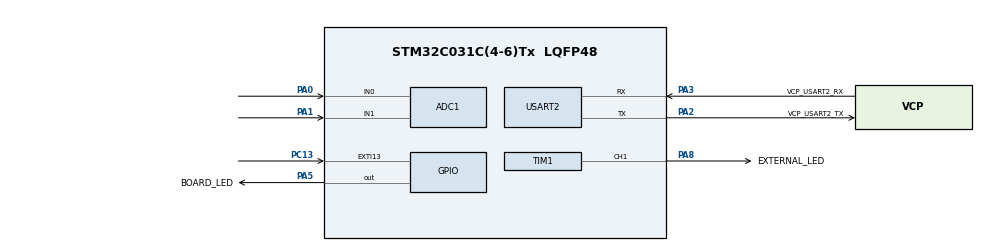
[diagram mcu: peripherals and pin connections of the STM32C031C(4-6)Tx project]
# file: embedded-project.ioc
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ADC1.ContinuousConvMode=ENABLE
ADC1.DMAContinuousRequests=ENABLE
ADC1.NbrOfConversionFlag=0
ADC1.Overrun=ADC_OVR_DATA_OVERWRITTEN
ADC1.SamplingTimeCommon1=ADC_SAMPLETIME_160CYCLES_5
ADC1.SelectedChannel=ADC_CHANNEL_0|ADC_CHANNEL_1
ADC1.master=1
Dma.ADC1.0.Direction=DMA_PERIPH_TO_MEMORY
Dma.ADC1.0.EventEnable=DISABLE
Dma.ADC1.0.Instance=DMA1_Channel1
Dma.ADC1.0.MemDataAlignment=DMA_MDATAALIGN_HALFWORD
Dma.ADC1.0.MemInc=DMA_MINC_ENABLE
Dma.ADC1.0.Mode=DMA_CIRCULAR
Dma.ADC1.0.PeriphDataAlignment=DMA_PDATAALIGN_HALFWORD
Dma.ADC1.0.PeriphInc=DMA_PINC_DISABLE
Dma.ADC1.0.Polarity=HAL_DMAMUX_REQ_GEN_RISING
Dma.ADC1.0.Priority=DMA_PRIORITY_LOW
Dma.ADC1.0.RequestNumber=1
Dma.ADC1.0.SignalID=NONE
Dma.ADC1.0.SyncEnable=DISABLE
Dma.ADC1.0.SyncPolarity=HAL_DMAMUX_SYNC_NO_EVENT
Dma.ADC1.0.SyncRequestNumber=1
Dma.ADC1.0.SyncSignalID=NONE
Dma.Request0=ADC1
Mcu.Family=STM32C0
Mcu.Name=STM32C031C(4-6)Tx
Mcu.Package=LQFP48
NVIC.DMA1_Channel1_IRQn=true\:0\:0\:false\:false\:true\:false\:true\:false
NVIC.EXTI4_15_IRQn=true\:0\:0\:false\:false\:true\:true\:true\:true
NVIC.TIM14_IRQn=true\:0\:0\:false\:false\:true\:true\:true\:true
NVIC.USART2_IRQn=true\:0\:0\:false\:false\:true\:true\:true\:true
PA0.Mode=IN0
PA0.Signal=ADC1_IN0
PA1.Mode=IN1
PA1.Signal=ADC1_IN1
PA13.GPIO_Label=DEBUG_SWDIO
PA13.Signal=DEBUG_SWDIO
PA14-BOOT0.GPIO_Label=DEBUG_SWCLK
PA14-BOOT0.Signal=DEBUG_SWCLK
PA2.GPIO_Label=VCP_USART2_TX
PA2.Mode=Asynchronous
PA2.Signal=USART2_TX
PA3.GPIO_Label=VCP_USART2_RX
PA3.Mode=Asynchronous
PA3.Signal=USART2_RX
PA5.GPIO_Label=BOARD_LED
PA5.Signal=GPIO_Output
PA8.GPIO_Label=EXTERNAL_LED
PA8.Signal=S_TIM1_CH1
PC13.GPIO_ModeDefaultEXTI=GPIO_MODE_IT_FALLING
PC13.Signal=GPXTI13
PC14-OSCX_IN\ (PC14).GPIO_Label=RCC_OSCX_IN
PC14-OSCX_IN\ (PC14).Mode=LSE-External-Oscillator
PC14-OSCX_IN\ (PC14).Signal=RCC_OSCX_IN
PC15-OSCX_OUT\ (PC15).GPIO_Label=RCC_OSCX_OUT
PC15-OSCX_OUT\ (PC15).Mode=LSE-External-Oscillator
PC15-OSCX_OUT\ (PC15).Signal=RCC_OSCX_OUT
PF0-OSC_IN\ (PF0).GPIO_Label=RCC_OSC_IN
PF0-OSC_IN\ (PF0).Signal=RCC_OSC_IN
PF1-OSC_OUT\ (PF1).GPIO_Label=RCC_OSC_OUT
PF1-OSC_OUT\ (PF1).Signal=RCC_OSC_OUT
ProjectManager.HeapSize=0x200
ProjectManager.StackSize=0x400
ProjectManager.TargetToolchain=Makefile
RCC.ADCFreq_Value=48000000
RCC.AHBFreq_Value=48000000
RCC.CortexFreq_Value=48000000
RCC.EXTERNAL_CLOCK_VALUE=12288000
RCC.HCLKFreq_Value=48000000
RCC.HSE_VALUE=48000000
RCC.HSISYSCLKDivider=RCC_HSI_DIV1
RCC.HSI_VALUE=48000000
RCC.SYSCLKFreq_VALUE=48000000
SH.S_TIM1_CH1.0=TIM1_CH1,PWM Generation1 CH1
TIM1.AutomaticOutput=TIM_AUTOMATICOUTPUT_ENABLE
TIM1.Channel-PWM\ Generation1\ CH1=TIM_CHANNEL_1
TIM1.Period=999
TIM1.Prescaler=47
TIM14.Period=74
TIM14.Prescaler=47999
USART2.VirtualMode-Asynchronous=VM_ASYNC
VP_TIM14_VS_ClockSourceINT.Mode=Enable_Timer
VP_TIM1_VS_ClockSourceINT.Mode=Internal
board=NUCLEO-C031C6

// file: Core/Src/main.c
/* USER CODE BEGIN Header */
/**
  ******************************************************************************
  * @file           : main.c
  * @brief          : Main program body
  ******************************************************************************
  * @attention
  *
  * Copyright (c) 2026 STMicroelectronics.
  * All rights reserved.
  *
  * This software is licensed under terms that can be found in the LICENSE file
  * in the root directory of this software component.
  * If no LICENSE file comes with this software, it is provided AS-IS.
  *
  ******************************************************************************
  */
/* USER CODE END Header */
#include "main.h"
#include "adc.h"
#include "dma.h"
#include "tim.h"
#include "usart.h"
#include "gpio.h"

/* USER CODE BEGIN Includes */
  #include "recruiting/telemetry/telemetry.h"
  #include "recruiting/button/button.h"
  #include "recruiting/cli/cli.h"
  #include "recruiting/fsm/fsm.h"

/* USER CODE END Includes */

void SystemClock_Config(void);

int main(void)
{

  /* MCU Configuration--------------------------------------------------------*/

  /* Reset of all peripherals, Initializes the Flash interface and the Systick. */
  HAL_Init();

  /* Configure the system clock */
  SystemClock_Config();

  /* Initialize all configured peripherals */
  MX_GPIO_Init();
  MX_DMA_Init();
  MX_ADC1_Init();
  MX_USART2_UART_Init();
  MX_TIM1_Init();
  MX_TIM14_Init();
  /* USER CODE BEGIN 2 */

  fsm_app_init();
  /* USER CODE END 2 */

  /* Infinite loop */
  /* USER CODE BEGIN WHILE */
  //static bool prev_cli_mode = false;
  while (1)
  {
    button_state_update();

    fsm_app_update();
    /* USER CODE END WHILE */

  }
}

void SystemClock_Config(void)
{
  RCC_OscInitTypeDef RCC_OscInitStruct = {0};
  RCC_ClkInitTypeDef RCC_ClkInitStruct = {0};

  __HAL_FLASH_SET_LATENCY(FLASH_LATENCY_1);

  /** Initializes the RCC Oscillators according to the specified parameters
  * in the RCC_OscInitTypeDef structure.
  */
  RCC_OscInitStruct.OscillatorType = RCC_OSCILLATORTYPE_HSI;
  RCC_OscInitStruct.HSIState = RCC_HSI_ON;
  RCC_OscInitStruct.HSIDiv = RCC_HSI_DIV1;
  RCC_OscInitStruct.HSICalibrationValue = RCC_HSICALIBRATION_DEFAULT;
  if (HAL_RCC_OscConfig(&RCC_OscInitStruct) != HAL_OK)
  {
    Error_Handler();
  }

  /** Initializes the CPU, AHB and APB buses clocks
  */
  RCC_ClkInitStruct.ClockType = RCC_CLOCKTYPE_HCLK|RCC_CLOCKTYPE_SYSCLK
                              |RCC_CLOCKTYPE_PCLK1;
  RCC_ClkInitStruct.SYSCLKSource = RCC_SYSCLKSOURCE_HSI;
  RCC_ClkInitStruct.SYSCLKDivider = RCC_SYSCLK_DIV1;
  RCC_ClkInitStruct.AHBCLKDivider = RCC_HCLK_DIV1;
  RCC_ClkInitStruct.APB1CLKDivider = RCC_APB1_DIV1;

  if (HAL_RCC_ClockConfig(&RCC_ClkInitStruct, FLASH_LATENCY_1) != HAL_OK)
  {
    Error_Handler();
  }
}

void Error_Handler(void)
{
  __disable_irq();
  while (1)
  {
  }
}
